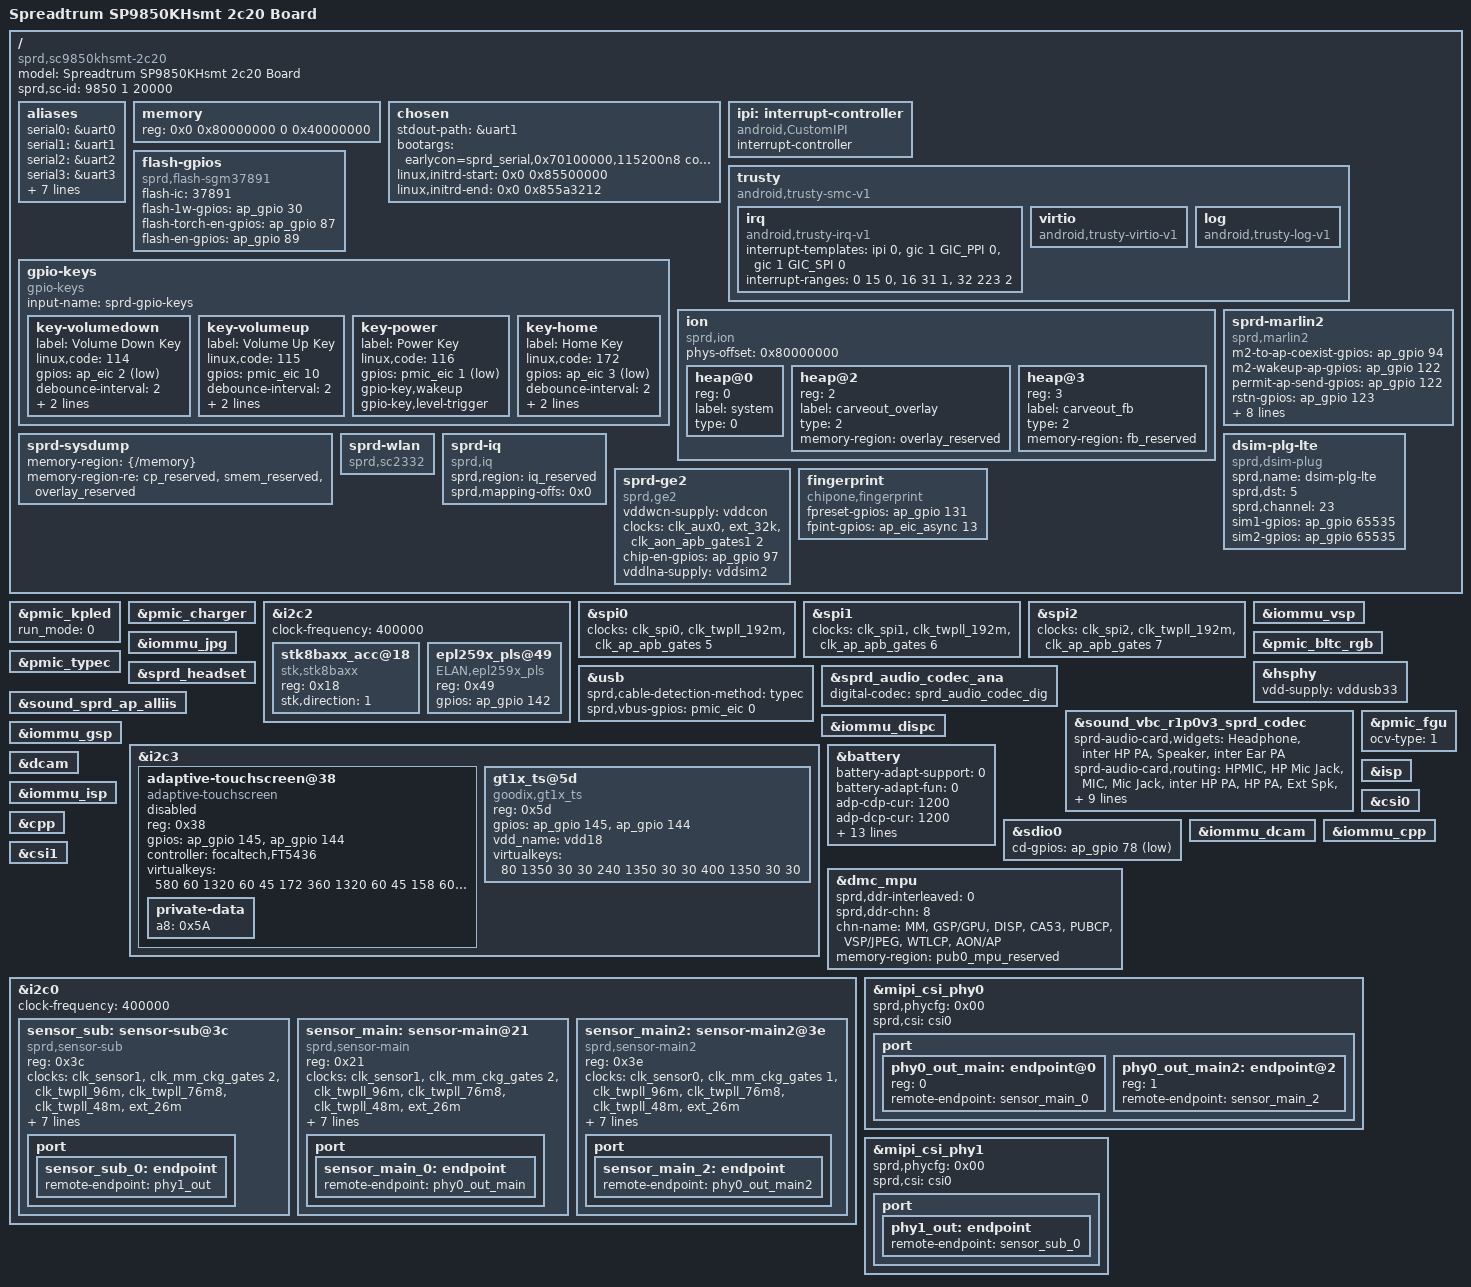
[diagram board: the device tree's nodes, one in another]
/*
 * Spreadtrum SP9850KH board DTS file
 *
 * Copyright (C) 2016, Spreadtrum Communications Inc.
 *
 * This file is licensed under a dual GPLv2 or X11 license.
 */

/dts-v1/;

#include "sc9850khsmt.dtsi"
#include "sp9850kh-common.dtsi"

/ {
	model = "Spreadtrum SP9850KHsmt 2c20 Board";

	compatible = "sprd,sc9850khsmt-2c20";

	sprd,sc-id = <9850 1 20000>;

	aliases {
		serial0 = &uart0;
		serial1 = &uart1;
		serial2 = &uart2;
		serial3 = &uart3;
		i2c0 = &i2c0;
		i2c1 = &i2c1;
		i2c2 = &i2c2;
		i2c3 = &i2c3;
		spi0 = &spi0;
		spi1 = &spi1;
		spi2 = &spi2;
	};

	memory{
		device_type = "memory";
		reg = <0x0 0x80000000 0 0x40000000>;
	};

	chosen {
		stdout-path = &uart1;
		bootargs = "earlycon=sprd_serial,0x70100000,115200n8 console=ttyS1,115200n8 loglevel=1 androidboot.hardware=sp9850kh_2c20 memblock=debug bootmem_debug=1";
		/* this initrd-start val will be changed by uboot  */
		linux,initrd-start = <0x0 0x85500000>;
		/* this initrd-end val will be changed by uboot  */
		linux,initrd-end = <0x0 0x855a3212>;
	};

	ipi: interrupt-controller {
		compatible = "android,CustomIPI";
		#interrupt-cells = <1>;
		interrupt-controller;
	};

	trusty {
		compatible = "android,trusty-smc-v1";

		irq {
			compatible = "android,trusty-irq-v1";
			interrupt-templates = <&ipi 0>,
						<&gic 1 GIC_PPI 0>,
						<&gic 1 GIC_SPI 0>;
			interrupt-ranges = < 0  15 0>,
						<16  31 1>,
						<32 223 2>;
		};

		virtio {
			compatible = "android,trusty-virtio-v1";
		};

		log {
			compatible = "android,trusty-log-v1";
		};
	};

	flash-gpios {
		compatible = "sprd,flash-sgm37891";
		flash-ic = <37891>;
		flash-1w-gpios = <&ap_gpio 30 0>;
		flash-torch-en-gpios = <&ap_gpio 87 0>;
		flash-en-gpios = <&ap_gpio 89 0>;
	};

	gpio-keys {
		compatible = "gpio-keys";
		input-name = "sprd-gpio-keys";
		status = "okay";

		key-volumedown {
			label = "Volume Down Key";
			linux,code = <114>;
			gpios = <&ap_eic 2 1>;
			debounce-interval = <2>;
			gpio-key,wakeup;
			gpio-key,level-trigger;
		};

		key-volumeup {
			label = "Volume Up Key";
			linux,code = <115>;
			gpios = <&pmic_eic 10 0>;
			debounce-interval = <2>;
			gpio-key,wakeup;
			gpio-key,level-trigger;
		};

		key-power {
			label = "Power Key";
			linux,code = <116>;
			gpios = <&pmic_eic 1 1>;
			gpio-key,wakeup;
			gpio-key,level-trigger;
		};
		key-home {
			label = "Home Key";
			linux,code = <172>;
			gpios = <&ap_eic 3 1>;
			debounce-interval = <2>;
			gpio-key,wakeup;
			gpio-key,level-trigger;
		};
	};

	ion {
		compatible = "sprd,ion";
		#address-cells = <1>;
		#size-cells = <0>;
		phys-offset = <0x80000000>;

		heap@0 {
			reg = <0>;
			label = "system";
			type = <0>;
		};

		heap@2 {
			reg = <2>;
			label = "carveout_overlay";
			type = <2>;
			memory-region = <&overlay_reserved>;
		};

		heap@3 {
			reg = <3>;
			label = "carveout_fb";
			type = <2>;
			memory-region = <&fb_reserved>;
		};
	};

	sprd-marlin2 {
		compatible = "sprd,marlin2";
		m2-to-ap-coexist-gpios = <&ap_gpio 94 0>;
		m2-wakeup-ap-gpios = <&ap_gpio 122 0>;
		permit-ap-send-gpios = <&ap_gpio 122 0>;
		rstn-gpios = <&ap_gpio 123 0>;
		chip-en-gpios = <&ap_gpio 97 0>;
		m2-to-ap-irq-gpios = <&ap_gpio 121 0>;
		vddwcn-supply = <&vddcon>;
		clock-names = "clk_32k","source","enable";
		clocks = <&clk_aux0>,<&ext_32k>,
			 <&clk_aon_apb_gates1 2>;
		sdhci-name = <&sdio1>;
		common_chip_en;
		power-ctl-disabled;
	};

	sprd-sysdump {
		memory-region = <&{/memory}>;
		memory-region-re = <&cp_reserved>, <&smem_reserved>,
				   <&overlay_reserved>;
	};

	sprd-wlan {
		compatible = "sprd,sc2332";
	};

	sprd-iq {
		compatible = "sprd,iq";
		sprd,region = <&iq_reserved>;
		sprd,mapping-offs = <0x0>;
	};

	dsim-plg-lte {
		compatible = "sprd,dsim-plug";
		sprd,name = "dsim-plg-lte";
		sprd,dst = <5>;
		sprd,channel = <23>;
		sim1-gpios = <&ap_gpio 65535 0>;
		sim2-gpios = <&ap_gpio 65535 0>;
	};

	sprd-ge2 {
		compatible = "sprd,ge2";
		vddwcn-supply = <&vddcon>;
		clock-names = "clk_32k","source","enable";
		clocks = <&clk_aux0>,<&ext_32k>,
			 <&clk_aon_apb_gates1 2>;
		chip-en-gpios = <&ap_gpio 97 0>;
		vddlna-supply = <&vddsim2>;
	};

	fingerprint {
		compatible = "chipone,fingerprint";
		fpreset-gpios = <&ap_gpio 131 0 >;
		fpint-gpios = <&ap_eic_async 13 0 >;
	};
};


&pmic_kpled{
	status = "okay";
	run_mode = <0>;
};

&pmic_charger{
	status = "okay";
};

&i2c2 {
	status = "okay";
	clock-frequency = <400000>;
	stk8baxx_acc@18{
		compatible = "stk,stk8baxx";
		reg = <0x18>;
		stk,direction = <1>;
		status = "okay";
	};

	epl259x_pls@49{
		compatible = "ELAN,epl259x_pls";
		reg = <0x49>;
		gpios = <&ap_gpio 142 0>;
		status = "okay";
	};
};

&spi0 {
	clocks = <&clk_spi0>, <&clk_twpll_192m>,
		<&clk_ap_apb_gates 5>;
};

&spi1 {
	clocks = <&clk_spi1>, <&clk_twpll_192m>,
		<&clk_ap_apb_gates 6>;
};

&spi2 {
	/*used for fingerprint sensor*/
	clocks = <&clk_spi2>, <&clk_twpll_192m>,
		<&clk_ap_apb_gates 7>;
	status = "okay";
};

&iommu_vsp {
	    status = "okay";
};

&iommu_jpg {
	status = "okay";
};

&pmic_bltc_rgb {
	status = "okay";
};

&pmic_typec {
	status = "okay";
};

&hsphy {
	vdd-supply = <&vddusb33>;
};

&usb {
	sprd,cable-detection-method = "typec";
	sprd,vbus-gpios = <&pmic_eic 0 0>;
};

&sprd_audio_codec_ana {
	status = "okay";
	digital-codec = <&sprd_audio_codec_dig>;
};

&sprd_headset {
	status = "okay";
};

&sound_vbc_r1p0v3_sprd_codec {
	status = "okay";
	sprd-audio-card,widgets =
		"Headphone", "inter HP PA",
		"Speaker", "inter Ear PA";
	sprd-audio-card,routing =
		"HPMIC", "HP Mic Jack",
		"MIC", "Mic Jack",
		"inter HP PA", "HP PA",
		"Ext Spk", "Spk PA",
		"inter Ear PA", "EAR",

		/* For vbc loopback */
		"Aud input", "AD Clk",
		"Aud input1", "AD Clk",
		"Aud input", "Digital ADCL Switch",
		"Aud input", "Digital ADCR Switch",
		"Aud input1", "Digital ADC1L Switch",
		"Aud input1", "Digital ADC1R Switch";
	/* ext_control_type, hook selection, mode, gpio share */
	sprd,spk-ext-pa-info = <0 0 0 0>;
	sprd,spk-ext-pa-gpio = <&ap_gpio 155 0>;
	sprd,spk-ext-pa-names = "ext_spk_r";
};

&sound_sprd_ap_alliis {
	status = "okay";
};

&iommu_dispc {
	status = "okay";
};

&iommu_gsp {
	status = "okay";
};

&i2c3 {
	status = "okay";
	adaptive-touchscreen@38 {
		status = "disabled";
		compatible = "adaptive-touchscreen";
		reg = <0x38>;
		gpios = <&ap_gpio 145 0
			&ap_gpio 144 0>;
		controller = "focaltech,FT5436";
		virtualkeys = <580 60 1320 60 45
				   172 360 1320 60 45
				   158 600 1320 60 45>;
		private-data {
			a8 = /bits/ 8 <0x5A>;
		};
	};

	gt1x_ts@5d{
		status = "okay";
		compatible = "goodix,gt1x_ts";
		reg = <0x5d>;
		gpios = <&ap_gpio 145 0
			&ap_gpio 144 0>;
		vdd_name = "vdd18";
		virtualkeys = <80 1350 30 30
					240 1350 30 30
					400 1350 30 30>;
	};
};

&battery {
	battery-adapt-support = <0>;
	battery-adapt-fun = <0>;
	adp-cdp-cur = <1200>;
	adp-dcp-cur = <1200>;
	adp-sdp-cur = <550>;
	adp-unknown-cur = <550>;
	chg-end-vol = <4350>;
	chg-end-vol-check = <4330>;
	chg-bat-safety-vol = <4430>;
	rechg-vol = <4270>;
	rsense-real = <200>;
	rint = <320>;
	cnom = <2780>;
	ocv-tab-vol = <4340 4243 4185 4132 4083 4037 3996
			3959 3921 3876 3842 3818 3800 3786
			3776 3768 3753 3731 3696 3663 3400>;
	ocv-tab-cap = <100  95   90   85   80   75   70
			65   60   55   50   45   40   35
			30   25   20   15   10   5    0>;
};

&pmic_fgu {
	ocv-type = <1>;
};

&sdio0 {
	cd-gpios = <&ap_gpio 78 1>;
};

&dmc_mpu {
	sprd,ddr-interleaved = <0>;
	sprd,ddr-chn = <8>;
	chn-name = "MM", "GSP/GPU", "DISP",
			"CA53", "PUBCP", "VSP/JPEG",
			"WTLCP", "AON/AP";
	memory-region = <&pub0_mpu_reserved>;
};

&dcam {
	status = "okay";
};

&iommu_dcam {
	status = "okay";
};

&isp {
	status = "okay";
};

&iommu_isp {
	status = "okay";
};

&csi0 {
	status = "okay";
};

&cpp {
	status = "okay";
};

&iommu_cpp {
	status = "okay";
};

&csi1 {
	status = "okay";
};

&i2c0 {
	status = "okay";
	clock-frequency = <400000>;

	sensor_sub: sensor-sub@3c {
		compatible = "sprd,sensor-sub";
		reg = <0x3c>;
		clock-names = "clk_src", "sensor_eb",
			"clk_96m", "clk_76m8",
			"clk_48m", "clk_26m";
		clocks = <&clk_sensor1>,
			<&clk_mm_ckg_gates 2>,
			<&clk_twpll_96m>,
			<&clk_twpll_76m8>,
			<&clk_twpll_48m>,
			<&ext_26m>;
		vddio-supply = <&vddcamio>;
		vddcama-supply = <&vddcama>;
		vddcamd-supply = <&vddcamd>;
		vddcammot-supply = <&vddcammot>;
		reset-gpios = <&ap_gpio 45 0>;
		power-down-gpios = <&ap_gpio 47 0>;
		host = "dcam0";
		port {
			sensor_sub_0: endpoint {
				remote-endpoint = <&phy1_out>;
			};
		};
	};

	sensor_main: sensor-main@21 {
		compatible = "sprd,sensor-main";
		reg = <0x21>;
		clock-names = "clk_src","sensor_eb",
			"clk_96m", "clk_76m8",
			"clk_48m", "clk_26m";
		clocks = <&clk_sensor1>,
			<&clk_mm_ckg_gates 2>,
			<&clk_twpll_96m>,
			<&clk_twpll_76m8>,
			<&clk_twpll_48m>,
			<&ext_26m>;
		vddio-supply = <&vddcamio>;
		vddcama-supply = <&vddcama>;
		vddcamd-supply = <&vddcamd>;
		vddcammot-supply = <&vddcammot>;
		reset-gpios = <&ap_gpio 41 0>;
		power-down-gpios = <&ap_gpio 40 0>;
		host = "dcam0";
		port {
			sensor_main_0: endpoint {
				remote-endpoint = <&phy0_out_main>;
			};
		};
	};

	sensor_main2: sensor-main2@3e {
		compatible = "sprd,sensor-main2";
		reg = <0x3e>;
		clock-names = "clk_src","sensor_eb",
			"clk_96m", "clk_76m8",
			"clk_48m", "clk_26m";
		clocks = <&clk_sensor0>,
			<&clk_mm_ckg_gates 1>,
			<&clk_twpll_96m>,
			<&clk_twpll_76m8>,
			<&clk_twpll_48m>,
			<&ext_26m>;
		vddio-supply = <&vddcamio>;
		vddcama-supply = <&vddcama>;
		vddcamd-supply = <&vddcamd>;
		vddcammot-supply = <&vddcammot>;
		reset-gpios = <&ap_gpio 44 0>;
		power-down-gpios = <&ap_gpio 46 0>;
		host = "dcam0";
		port {
			sensor_main_2: endpoint {
				remote-endpoint = <&phy0_out_main2>;
			};
		};
	};
};

&mipi_csi_phy0 {
	status = "okay";
	sprd,phycfg = <0x00>;
	sprd,csi = <&csi0>;
	port {
		#address-cells = <1>;
		#size-cells = <0>;
		phy0_out_main: endpoint@0 {
			reg = <0>;
			remote-endpoint = <&sensor_main_0>;
		};
		phy0_out_main2: endpoint@2 {
			reg = <1>;
			remote-endpoint = <&sensor_main_2>;
		};
	};
};

&mipi_csi_phy1 {
	status = "okay";
	sprd,phycfg = <0x00>;
	sprd,csi = <&csi0>;
	port {
		phy1_out: endpoint {
			remote-endpoint = <&sensor_sub_0>;
		};
	};
};

